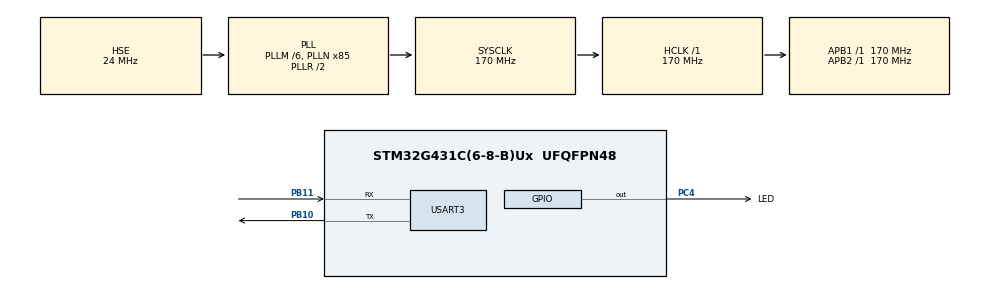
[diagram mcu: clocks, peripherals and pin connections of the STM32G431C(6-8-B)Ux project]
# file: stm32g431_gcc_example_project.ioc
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Dma.Request0=USART3_RX
Dma.Request1=USART3_TX
Dma.USART3_RX.0.Direction=DMA_PERIPH_TO_MEMORY
Dma.USART3_RX.0.EventEnable=DISABLE
Dma.USART3_RX.0.Instance=DMA1_Channel1
Dma.USART3_RX.0.MemDataAlignment=DMA_MDATAALIGN_BYTE
Dma.USART3_RX.0.MemInc=DMA_MINC_ENABLE
Dma.USART3_RX.0.Mode=DMA_NORMAL
Dma.USART3_RX.0.PeriphDataAlignment=DMA_PDATAALIGN_BYTE
Dma.USART3_RX.0.PeriphInc=DMA_PINC_DISABLE
Dma.USART3_RX.0.Polarity=HAL_DMAMUX_REQ_GEN_RISING
Dma.USART3_RX.0.Priority=DMA_PRIORITY_LOW
Dma.USART3_RX.0.RequestNumber=1
Dma.USART3_RX.0.SignalID=NONE
Dma.USART3_RX.0.SyncEnable=DISABLE
Dma.USART3_RX.0.SyncPolarity=HAL_DMAMUX_SYNC_NO_EVENT
Dma.USART3_RX.0.SyncRequestNumber=1
Dma.USART3_RX.0.SyncSignalID=NONE
Dma.USART3_TX.1.Direction=DMA_MEMORY_TO_PERIPH
Dma.USART3_TX.1.EventEnable=DISABLE
Dma.USART3_TX.1.Instance=DMA1_Channel2
Dma.USART3_TX.1.MemDataAlignment=DMA_MDATAALIGN_BYTE
Dma.USART3_TX.1.MemInc=DMA_MINC_ENABLE
Dma.USART3_TX.1.Mode=DMA_NORMAL
Dma.USART3_TX.1.PeriphDataAlignment=DMA_PDATAALIGN_BYTE
Dma.USART3_TX.1.PeriphInc=DMA_PINC_DISABLE
Dma.USART3_TX.1.Polarity=HAL_DMAMUX_REQ_GEN_RISING
Dma.USART3_TX.1.Priority=DMA_PRIORITY_LOW
Dma.USART3_TX.1.RequestNumber=1
Dma.USART3_TX.1.SignalID=NONE
Dma.USART3_TX.1.SyncEnable=DISABLE
Dma.USART3_TX.1.SyncPolarity=HAL_DMAMUX_SYNC_NO_EVENT
Dma.USART3_TX.1.SyncRequestNumber=1
Dma.USART3_TX.1.SyncSignalID=NONE
Mcu.Family=STM32G4
Mcu.Name=STM32G431C(6-8-B)Ux
Mcu.Package=UFQFPN48
NVIC.DMA1_Channel1_IRQn=true\:0\:0\:false\:false\:true\:false\:true\:true
NVIC.DMA1_Channel2_IRQn=true\:0\:0\:false\:false\:true\:false\:true\:true
NVIC.PriorityGroup=NVIC_PRIORITYGROUP_4
NVIC.USART3_IRQn=true\:0\:0\:false\:false\:true\:true\:true\:true
PA13.Mode=Serial_Wire
PA13.Signal=SYS_JTMS-SWDIO
PA14.Mode=Serial_Wire
PA14.Signal=SYS_JTCK-SWCLK
PB10.Mode=Asynchronous
PB10.Signal=USART3_TX
PB11.Mode=Asynchronous
PB11.Signal=USART3_RX
PC14-OSC32_IN.Mode=LSE-External-Oscillator
PC14-OSC32_IN.Signal=RCC_OSC32_IN
PC15-OSC32_OUT.Mode=LSE-External-Oscillator
PC15-OSC32_OUT.Signal=RCC_OSC32_OUT
PC4.GPIO_Label=LED
PC4.Signal=GPIO_Output
PF0-OSC_IN.Mode=HSE-External-Oscillator
PF0-OSC_IN.Signal=RCC_OSC_IN
PF1-OSC_OUT.Mode=HSE-External-Oscillator
PF1-OSC_OUT.Signal=RCC_OSC_OUT
ProjectManager.HeapSize=0x200
ProjectManager.StackSize=0x400
ProjectManager.TargetToolchain=Makefile
RCC.ADC12Freq_Value=170000000
RCC.AHBFreq_Value=170000000
RCC.APB1Freq_Value=170000000
RCC.APB1TimFreq_Value=170000000
RCC.APB2Freq_Value=170000000
RCC.APB2TimFreq_Value=170000000
RCC.CortexFreq_Value=170000000
RCC.EXTERNAL_CLOCK_VALUE=12288000
RCC.HCLKFreq_Value=170000000
RCC.HSE_VALUE=24000000
RCC.HSI48_VALUE=48000000
RCC.HSI_VALUE=16000000
RCC.PLLM=RCC_PLLM_DIV6
RCC.PLLN=85
RCC.PLLSourceVirtual=RCC_PLLSOURCE_HSE
RCC.SYSCLKFreq_VALUE=170000000
RCC.SYSCLKSource=RCC_SYSCLKSOURCE_PLLCLK
RCC.USBFreq_Value=170000000
RCC.VCOOutputFreq_Value=340000000
USART3.VirtualMode-Asynchronous=VM_ASYNC
VP_SYS_VS_DBSignals.Mode=DisableDeadBatterySignals
board=custom

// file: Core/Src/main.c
/* USER CODE BEGIN Header */
/**
  ******************************************************************************
  * @file           : main.c
  * @brief          : LinRTOS 测试入口 —— 硬件初始化 + 启动 app_entry
  ******************************************************************************
  */
/* USER CODE END Header */

#include "main.h"
#include "usart.h"
#include "linRTOS.h"
#include "port.h"
#include "cli_io.h"
#include "cli_critical.h"

/* USER CODE BEGIN PV */
uint8_t s_rx_buf[UART_RX_BUF_SIZE];
/* USER CODE END PV */

void SystemClock_Config(void);
static void MX_GPIO_Init(void);
static void MX_DMA_Init(void);

int main(void)
{
    HAL_Init();
    SystemClock_Config();

    MX_GPIO_Init();
    MX_DMA_Init();
    MX_USART3_UART_Init();

    cli_printk("=== LinRTOS Test Boot ===\r\n");

    HAL_UARTEx_ReceiveToIdle_DMA(&huart3, s_rx_buf, UART_RX_BUF_SIZE);

    rtos_scheduler_start();

    /* 永远不会到达 */
    for (;;);
}

void SystemClock_Config(void)
{
    RCC_OscInitTypeDef RCC_OscInitStruct = {0};
    RCC_ClkInitTypeDef RCC_ClkInitStruct = {0};

    HAL_PWREx_ControlVoltageScaling(PWR_REGULATOR_VOLTAGE_SCALE1_BOOST);

    RCC_OscInitStruct.OscillatorType = RCC_OSCILLATORTYPE_HSE;
    RCC_OscInitStruct.HSEState = RCC_HSE_ON;
    RCC_OscInitStruct.PLL.PLLState = RCC_PLL_ON;
    RCC_OscInitStruct.PLL.PLLSource = RCC_PLLSOURCE_HSE;
    RCC_OscInitStruct.PLL.PLLM = RCC_PLLM_DIV6;
    RCC_OscInitStruct.PLL.PLLN = 85;
    RCC_OscInitStruct.PLL.PLLP = RCC_PLLP_DIV2;
    RCC_OscInitStruct.PLL.PLLQ = RCC_PLLQ_DIV2;
    RCC_OscInitStruct.PLL.PLLR = RCC_PLLR_DIV2;
    if (HAL_RCC_OscConfig(&RCC_OscInitStruct) != HAL_OK)
    {
        Error_Handler();
    }

    RCC_ClkInitStruct.ClockType = RCC_CLOCKTYPE_HCLK|RCC_CLOCKTYPE_SYSCLK
                                |RCC_CLOCKTYPE_PCLK1|RCC_CLOCKTYPE_PCLK2;
    RCC_ClkInitStruct.SYSCLKSource = RCC_SYSCLKSOURCE_PLLCLK;
    RCC_ClkInitStruct.AHBCLKDivider = RCC_SYSCLK_DIV1;
    RCC_ClkInitStruct.APB1CLKDivider = RCC_HCLK_DIV1;
    RCC_ClkInitStruct.APB2CLKDivider = RCC_HCLK_DIV1;

    if (HAL_RCC_ClockConfig(&RCC_ClkInitStruct, FLASH_LATENCY_4) != HAL_OK)
    {
        Error_Handler();
    }
}

static void MX_DMA_Init(void)
{
    __HAL_RCC_DMAMUX1_CLK_ENABLE();
    __HAL_RCC_DMA1_CLK_ENABLE();
}

static void MX_GPIO_Init(void)
{
    __HAL_RCC_GPIOB_CLK_ENABLE();
}

/* ============================================================
 * 🛡️ 临界区 —— 映射到 LinRTOS PRIMASK 临界区
 * ============================================================ */

static uint32_t s_cli_critical_state;
static int s_cli_critical_nest = 0;

void cli_enter_critical(void)
{
    if (s_cli_critical_nest++ == 0) {
        s_cli_critical_state = rtos_port_enter_critical();
    }
}

void cli_exit_critical(void)
{
    if (s_cli_critical_nest > 0 && --s_cli_critical_nest == 0) {
        rtos_port_exit_critical(s_cli_critical_state);
    }
}

int cli_in_exception(void)
{
    return rtos_port_is_in_isr();
}

/* ============================================================
 * 🖨️ 字符输出 —— 直接调用 HAL UART 发送一个字符
 * ============================================================ */

void cli_putc(char ch)
{
    HAL_UART_Transmit(&huart3, (uint8_t *)&ch, 1, 100);
}

void HAL_UARTEx_RxEventCallback(UART_HandleTypeDef *huart, uint16_t Size)
{
    if (huart->Instance == USART3) {
        cli_in_push((_u8 *)s_rx_buf, (int)Size);
    }
}

void Error_Handler(void)
{
    __disable_irq();
    while (1) {}
}
